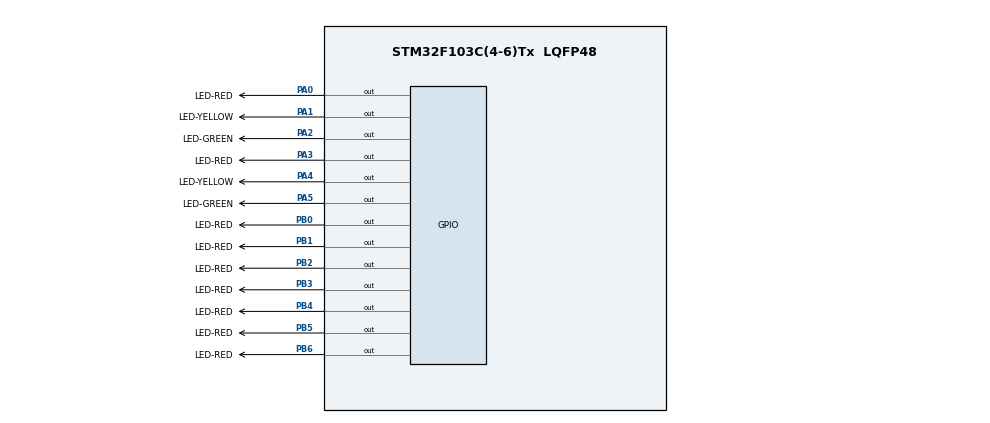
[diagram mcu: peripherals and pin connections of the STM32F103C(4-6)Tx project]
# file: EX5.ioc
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Mcu.Family=STM32F1
Mcu.Name=STM32F103C(4-6)Tx
Mcu.Package=LQFP48
NVIC.PriorityGroup=NVIC_PRIORITYGROUP_4
PA0-WKUP.GPIO_Label=LED-RED
PA0-WKUP.Signal=GPIO_Output
PA1.GPIO_Label=LED-YELLOW
PA1.Signal=GPIO_Output
PA2.GPIO_Label=LED-GREEN
PA2.Signal=GPIO_Output
PA3.GPIO_Label=LED-RED
PA3.Signal=GPIO_Output
PA4.GPIO_Label=LED-YELLOW
PA4.Signal=GPIO_Output
PA5.GPIO_Label=LED-GREEN
PA5.Signal=GPIO_Output
PB0.GPIO_Label=LED-RED
PB0.Signal=GPIO_Output
PB1.GPIO_Label=LED-RED
PB1.Signal=GPIO_Output
PB2.GPIO_Label=LED-RED
PB2.Signal=GPIO_Output
PB3.GPIO_Label=LED-RED
PB3.Signal=GPIO_Output
PB4.GPIO_Label=LED-RED
PB4.Signal=GPIO_Output
PB5.GPIO_Label=LED-RED
PB5.Signal=GPIO_Output
PB6.GPIO_Label=LED-RED
PB6.Signal=GPIO_Output
ProjectManager.HeapSize=0x200
ProjectManager.StackSize=0x400
ProjectManager.TargetToolchain=STM32CubeIDE
RCC.APB1Freq_Value=8000000
RCC.APB2Freq_Value=8000000
VP_SYS_VS_ND.Mode=No_Debug
board=custom

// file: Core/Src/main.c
/* USER CODE BEGIN Header */
/**
  ******************************************************************************
  * @file           : main.c
  * @brief          : Main program body
  ******************************************************************************
  * @attention
  *
  * <h2><center>&copy; Copyright (c) 2025 STMicroelectronics.
  * All rights reserved.</center></h2>
  *
  * This software component is licensed by ST under BSD 3-Clause license,
  * the "License"; You may not use this file except in compliance with the
  * License. You may obtain a copy of the License at:
  *                        opensource.org/licenses/BSD-3-Clause
  *
  ******************************************************************************
  */
/* USER CODE END Header */
#include "main.h"
#define SEG_A_Pin GPIO_PIN_0
#define SEG_B_Pin GPIO_PIN_1
#define SEG_C_Pin GPIO_PIN_2
#define SEG_D_Pin GPIO_PIN_3
#define SEG_E_Pin GPIO_PIN_4
#define SEG_F_Pin GPIO_PIN_5
#define SEG_G_Pin GPIO_PIN_6
#define SEG_Port  GPIOB
// Định nghĩa các chân cho Làn 1 (DỌC)
#define LANE1_RED_PORT      GPIOA
#define LANE1_RED_PIN       GPIO_PIN_0
#define LANE1_YELLOW_PORT   GPIOA
#define LANE1_YELLOW_PIN    GPIO_PIN_1
#define LANE1_GREEN_PORT    GPIOA
#define LANE1_GREEN_PIN     GPIO_PIN_2

// Định nghĩa các chân cho Làn 2 (NGANG)
#define LANE2_RED_PORT      GPIOA
#define LANE2_RED_PIN       GPIO_PIN_3
#define LANE2_YELLOW_PORT   GPIOA
#define LANE2_YELLOW_PIN    GPIO_PIN_4
#define LANE2_GREEN_PORT    GPIOA
#define LANE2_GREEN_PIN     GPIO_PIN_5

void SystemClock_Config(void);
static void MX_GPIO_Init(void);
void display7SEG(int num);

int main(void)
{

  /* MCU Configuration--------------------------------------------------------*/

  /* Reset of all peripherals, Initializes the Flash interface and the Systick. */
  HAL_Init();

  /* Configure the system clock */
  SystemClock_Config();

  /* Initialize all configured peripherals */
  MX_GPIO_Init();
  /* USER CODE BEGIN 2 */
  	  HAL_GPIO_WritePin(LANE1_RED_PORT, LANE1_RED_PIN, GPIO_PIN_SET);
      HAL_GPIO_WritePin(LANE1_YELLOW_PORT, LANE1_YELLOW_PIN, GPIO_PIN_SET);
      HAL_GPIO_WritePin(LANE1_GREEN_PORT, LANE1_GREEN_PIN, GPIO_PIN_SET);
      HAL_GPIO_WritePin(LANE2_RED_PORT, LANE2_RED_PIN, GPIO_PIN_SET);
      HAL_GPIO_WritePin(LANE2_YELLOW_PORT, LANE2_YELLOW_PIN, GPIO_PIN_SET);
      HAL_GPIO_WritePin(LANE2_GREEN_PORT, LANE2_GREEN_PIN, GPIO_PIN_SET);
  /* USER CODE END 2 */

  /* Infinite loop */
  while (1)
  {

	  // ----- Trạng thái 1: Làn 1 XANH (3s), Làn 2 ĐỎ -----
	 	      // Bật đèn Xanh Làn 1 (BẬT = RESET).
	 	      HAL_GPIO_WritePin(LANE1_GREEN_PORT, LANE1_GREEN_PIN, GPIO_PIN_RESET);
	 	      HAL_GPIO_WritePin(LANE1_YELLOW_PORT, LANE1_YELLOW_PIN, GPIO_PIN_SET);
	 	      HAL_GPIO_WritePin(LANE1_RED_PORT, LANE1_RED_PIN, GPIO_PIN_SET);

	 	      // Bật đèn Đỏ Làn 2 (BẬT = RESET).
	 	      HAL_GPIO_WritePin(LANE2_RED_PORT, LANE2_RED_PIN, GPIO_PIN_RESET);
	 	      HAL_GPIO_WritePin(LANE2_GREEN_PORT, LANE2_GREEN_PIN, GPIO_PIN_SET);
	 	      HAL_GPIO_WritePin(LANE2_YELLOW_PORT, LANE2_YELLOW_PIN, GPIO_PIN_SET);

	 	      for (int i = 2; i >= 0; i--) {
	 	            display7SEG(i);
	 	            HAL_Delay(1000);
	 	        }

	 	      // ----- Trạng thái 2: Làn 1 VÀNG (2s), Làn 2 vẫn ĐỎ -----
	 	      // Tắt đèn Xanh Làn 1, bật đèn Vàng Làn 1.
	 	      HAL_GPIO_WritePin(LANE1_GREEN_PORT, LANE1_GREEN_PIN, GPIO_PIN_SET);
	 	      HAL_GPIO_WritePin(LANE1_YELLOW_PORT, LANE1_YELLOW_PIN, GPIO_PIN_RESET);

	 	     for (int i = 1; i >= 0; i--) {
	 	             display7SEG(i);
	 	             HAL_Delay(1000);
	 	         }

	 	      // ----- Trạng thái 3: Làn 1 ĐỎ, Làn 2 XANH (3s) -----
	 	      // Tắt đèn Vàng Làn 1, bật đèn Đỏ Làn 1.
	 	      HAL_GPIO_WritePin(LANE1_YELLOW_PORT, LANE1_YELLOW_PIN, GPIO_PIN_SET);
	 	      HAL_GPIO_WritePin(LANE1_RED_PORT, LANE1_RED_PIN, GPIO_PIN_RESET);

	 	      // Tắt đèn Đỏ Làn 2, bật đèn Xanh Làn 2.
	 	      HAL_GPIO_WritePin(LANE2_RED_PORT, LANE2_RED_PIN, GPIO_PIN_SET);
	 	      HAL_GPIO_WritePin(LANE2_GREEN_PORT, LANE2_GREEN_PIN, GPIO_PIN_RESET);

	 	     for (int i = 4; i >= 2; i--) {
	 	            display7SEG(i);
	 	            HAL_Delay(1000);
	 	        }

	 	      // ----- Trạng thái 4: Làn 1 vẫn ĐỎ, Làn 2 VÀNG (2s) -----
	 	      // Tắt đèn Xanh Làn 2, bật đèn Vàng Làn 2.
	 	      HAL_GPIO_WritePin(LANE2_GREEN_PORT, LANE2_GREEN_PIN, GPIO_PIN_SET);
	 	      HAL_GPIO_WritePin(LANE2_YELLOW_PORT, LANE2_YELLOW_PIN, GPIO_PIN_RESET);

	 	     for (int i = 1; i >= 0; i--) {
	 	             display7SEG(i);
	 	             HAL_Delay(1000);
	 	         }

  }
}

void SystemClock_Config(void)
{
  RCC_OscInitTypeDef RCC_OscInitStruct = {0};
  RCC_ClkInitTypeDef RCC_ClkInitStruct = {0};

  /** Initializes the RCC Oscillators according to the specified parameters
  * in the RCC_OscInitTypeDef structure.
  */
  RCC_OscInitStruct.OscillatorType = RCC_OSCILLATORTYPE_HSI;
  RCC_OscInitStruct.HSIState = RCC_HSI_ON;
  RCC_OscInitStruct.HSICalibrationValue = RCC_HSICALIBRATION_DEFAULT;
  RCC_OscInitStruct.PLL.PLLState = RCC_PLL_NONE;
  if (HAL_RCC_OscConfig(&RCC_OscInitStruct) != HAL_OK)
  {
    Error_Handler();
  }
  /** Initializes the CPU, AHB and APB buses clocks
  */
  RCC_ClkInitStruct.ClockType = RCC_CLOCKTYPE_HCLK|RCC_CLOCKTYPE_SYSCLK
                              |RCC_CLOCKTYPE_PCLK1|RCC_CLOCKTYPE_PCLK2;
  RCC_ClkInitStruct.SYSCLKSource = RCC_SYSCLKSOURCE_HSI;
  RCC_ClkInitStruct.AHBCLKDivider = RCC_SYSCLK_DIV1;
  RCC_ClkInitStruct.APB1CLKDivider = RCC_HCLK_DIV1;
  RCC_ClkInitStruct.APB2CLKDivider = RCC_HCLK_DIV1;

  if (HAL_RCC_ClockConfig(&RCC_ClkInitStruct, FLASH_LATENCY_0) != HAL_OK)
  {
    Error_Handler();
  }
}

void display7SEG(int num)
{
  // Mảng mã hóa cho LED 7 đoạn Common Anode (0=ON, 1=OFF)
  // Thứ tự bit: g, f, e, d, c, b, a
  const uint8_t segmentCodes[10] = {
    0x40,  // Số 0, 0110 0000
    0x79,  // Số 1, 0111 1001
    0x24,  // Số 2, 0010 0100
    0x30,  // Số 3, 0011 0000
    0x19,  // Số 4, 0001 1001
    0x12,  // Số 5, 0001 0010
    0x02,  // Số 6, 0000 0010
    0x78,  // Số 7, 0111 1000
    0x00,  // Số 8, 0000 0000
	0x10   // Số 9, 0001 0000
  };

  if (num >= 0 && num <= 9)
  {
    uint8_t code = segmentCodes[num];
    HAL_GPIO_WritePin(SEG_Port, SEG_A_Pin, (code >> 0) & 0x01);
    HAL_GPIO_WritePin(SEG_Port, SEG_B_Pin, (code >> 1) & 0x01);
    HAL_GPIO_WritePin(SEG_Port, SEG_C_Pin, (code >> 2) & 0x01);
    HAL_GPIO_WritePin(SEG_Port, SEG_D_Pin, (code >> 3) & 0x01);
    HAL_GPIO_WritePin(SEG_Port, SEG_E_Pin, (code >> 4) & 0x01);
    HAL_GPIO_WritePin(SEG_Port, SEG_F_Pin, (code >> 5) & 0x01);
    HAL_GPIO_WritePin(SEG_Port, SEG_G_Pin, (code >> 6) & 0x01);
  }
}
static void MX_GPIO_Init(void)
{
  GPIO_InitTypeDef GPIO_InitStruct = {0};

  /* GPIO Ports Clock Enable */
  __HAL_RCC_GPIOA_CLK_ENABLE();
  __HAL_RCC_GPIOB_CLK_ENABLE();

  /*Configure GPIO pin Output Level */
  HAL_GPIO_WritePin(GPIOA, LED_RED_Pin|LED_YELLOW_Pin|LED_GREEN_Pin|LED_REDA3_Pin
                          |LED_YELLOWA4_Pin|LED_GREENA5_Pin, GPIO_PIN_RESET);

  /*Configure GPIO pin Output Level */
  HAL_GPIO_WritePin(GPIOB, LED_REDB0_Pin|LED_REDB1_Pin|LED_REDB2_Pin|LED_REDB3_Pin
                          |LED_REDB4_Pin|LED_REDB5_Pin|LED_REDB6_Pin, GPIO_PIN_RESET);

  /*Configure GPIO pins : LED_RED_Pin LED_YELLOW_Pin LED_GREEN_Pin LED_REDA3_Pin
                           LED_YELLOWA4_Pin LED_GREENA5_Pin */
  GPIO_InitStruct.Pin = LED_RED_Pin|LED_YELLOW_Pin|LED_GREEN_Pin|LED_REDA3_Pin
                          |LED_YELLOWA4_Pin|LED_GREENA5_Pin;
  GPIO_InitStruct.Mode = GPIO_MODE_OUTPUT_PP;
  GPIO_InitStruct.Pull = GPIO_NOPULL;
  GPIO_InitStruct.Speed = GPIO_SPEED_FREQ_LOW;
  HAL_GPIO_Init(GPIOA, &GPIO_InitStruct);

  /*Configure GPIO pins : LED_REDB0_Pin LED_REDB1_Pin LED_REDB2_Pin LED_REDB3_Pin
                           LED_REDB4_Pin LED_REDB5_Pin LED_REDB6_Pin */
  GPIO_InitStruct.Pin = LED_REDB0_Pin|LED_REDB1_Pin|LED_REDB2_Pin|LED_REDB3_Pin
                          |LED_REDB4_Pin|LED_REDB5_Pin|LED_REDB6_Pin;
  GPIO_InitStruct.Mode = GPIO_MODE_OUTPUT_PP;
  GPIO_InitStruct.Pull = GPIO_NOPULL;
  GPIO_InitStruct.Speed = GPIO_SPEED_FREQ_LOW;
  HAL_GPIO_Init(GPIOB, &GPIO_InitStruct);

}

void Error_Handler(void)
{
  __disable_irq();
  while (1)
  {
  }
}

/************************ (C) COPYRIGHT STMicroelectronics *****END OF FILE****/
